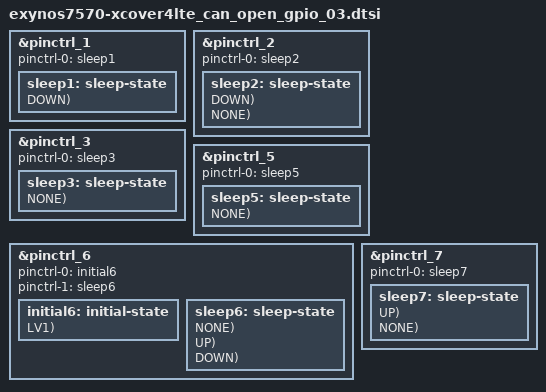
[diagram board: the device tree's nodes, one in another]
/*
 * Copyright (c) 2015 Samsung Electronics Co., Ltd.
 *		http://www.samsung.com
 *
 * This program is free software; you can redistribute it and/or modify
 * it under the terms of the GNU General Public License version 2 as
 * published by the Free Software Foundation.
 */

#include "exynos_gpio_config_macros.dtsi"

/* 0x148C_0000(DISPAUD): gpz1 */
&pinctrl_1 {
	pinctrl-names = "sleep";
	pinctrl-0 = <&sleep1>;
	sleep1: sleep-state {
		PIN_SLP(gpz1-0, INPUT, DOWN);	/* AMP/CODEC_I2S_SYNC :I2S1_LRCK*/
		PIN_SLP(gpz1-1, INPUT, DOWN);	/* AMP_I2S_BCLK */
		PIN_SLP(gpz1-2, INPUT, DOWN);	/* AMP/CODEC_I2S_SDI */
		PIN_SLP(gpz1-3, INPUT, DOWN);	/* AMP/CODEC_I2S_SDO */
		PIN_SLP(gpz1-4, INPUT, DOWN);	/* CODEC_I2S_CLK */
		PIN_SLP(gpz1-5, INPUT, DOWN);	/* SPK_I2C_IN */
		PIN_SLP(gpz1-6, INPUT, DOWN);	/* FM_SPDY_TO_S610 */
	};
};

/* 0x139E_0000(FP): gpc7 */
&pinctrl_2 {
	pinctrl-names = "sleep";
	pinctrl-0 = <&sleep2>;
	sleep2: sleep-state {
		PIN_SLP(gpc7-0, INPUT, DOWN);	/* NC */
		PIN_SLP(gpc7-1, PREV, NONE);	/* PROX_LED_LDO */
		PIN_SLP(gpc7-2, INPUT, DOWN);	/* NC */
		PIN_SLP(gpc7-3, INPUT, DOWN);	/* NC */
		PIN_SLP(gpc7-4, PREV, NONE);	/* FM_LNA_EN */
	};
};

/* 0x1375_0000(FSYS): gpr0~4 */
&pinctrl_3 {
	pinctrl-names = "sleep";
	pinctrl-0 = <&sleep3>;
	sleep3: sleep-state {
		PIN_SLP(gpr0-1, INPUT, NONE);	/* EMMC_CMD */
	};
};

/* 0x1053_0000(MIF): gpm0 */
/* &pinctrl_4 */

/* 0x139C_0000(NFC): gpc2 */
&pinctrl_5 {
	pinctrl-names = "sleep";
	pinctrl-0 = <&sleep5>;
	sleep5: sleep-state {
		PIN_SLP(gpc2-0, INPUT, NONE);	/* LCD_BL_SDA_1P8 */
		PIN_SLP(gpc2-1, INPUT, NONE);	/* LCD_BL_SCL_1P8 */
		PIN_SLP(gpc2-2, PREV, NONE);	/* NFC_PD */
		PIN_SLP(gpc2-3, PREV, NONE);	/* NFC_CLK_REQ */
	};
};

/* 0x139B_0000(TOP): gpc0~1,4, gpd1, gpe0, gpf0~1,3 */
&pinctrl_6 {
	pinctrl-names = "default","sleep";
	pinctrl-0 = <&initial6>;
	pinctrl-1 = <&sleep6>;
	initial6: initial-state {
		PIN_IN(gpd1-2, NONE, LV1);	/* HW_REV0 */
		PIN_IN(gpd1-3, NONE, LV1);	/* HW_REV1 */
		PIN_IN(gpd1-4, NONE, LV1);	/* HW_REV2 */
		PIN_IN(gpd1-5, NONE, LV1);	/* SIM MODE */
		PIN_IN(gpe0-2, DOWN, LV1);	/* NC */

		PIN_OUT_SET(gpf1-1, 0, LV1);	/* MUX_SEL */
	};
	sleep6: sleep-state {
		PIN_SLP(gpc0-1, PREV, NONE);	/* PANEL_EN_P */
		PIN_SLP(gpc0-2, PREV, NONE);	/* PANEL_EN_N */

		PIN_SLP(gpc1-2, PREV, UP);	/* MUIC_I2C_SDA */
		PIN_SLP(gpc1-3, PREV, UP);	/* MUIC_I2C_SCL */

		PIN_SLP(gpc4-0, INPUT, UP);	/* NFC_SDA_1P8 */
		PIN_SLP(gpc4-1, INPUT, UP);	/* NFC_SCL_1P8 */
		PIN_SLP(gpc4-2, INPUT, UP);	/* SENSOR_I2C_SDA */
		PIN_SLP(gpc4-3, INPUT, UP);	/* SENSOR_I2C_SCL */

		PIN_SLP(gpd1-0, PREV, DOWN);	/* NFC_FIRM */
		PIN_SLP(gpd1-1, INPUT, DOWN);	/* CAM_RST_N */
		PIN_SLP(gpd1-2, INPUT, NONE);	/* HW_REV0 */
		PIN_SLP(gpd1-3, INPUT, NONE);	/* HW_REV1 */
		PIN_SLP(gpd1-4, INPUT, NONE);	/* HW_REV2 */
		PIN_SLP(gpd1-5, INPUT, NONE);	/* SIM MODE */
		PIN_SLP(gpd1-6, INPUT, DOWN);	/* VTCAM_RST_N */

		PIN_SLP(gpe0-0, INPUT, DOWN);	/* CAM_MCLK */
		PIN_SLP(gpe0-1, INPUT, DOWN);	/* VTCAM_MCLK */
		PIN_SLP(gpe0-2, INPUT, DOWN);	/* NC */

		PIN_SLP(gpf0-0, INPUT, DOWN);	/* CAM_SDA_1P8 */
		PIN_SLP(gpf0-1, INPUT, DOWN);	/* CAM_SCL_1P8 */
		PIN_SLP(gpf0-2, INPUT, DOWN);	/* CAM_AF_EEP_SDA_1P8 */
		PIN_SLP(gpf0-3, INPUT, DOWN);	/* CAM_AF_EEP_SCL_1P8 */

		PIN_SLP(gpf1-0, OUT1, NONE);	/* NFC_PERI_PWR_EN */
		PIN_SLP(gpf1-1, PREV, NONE);	/* MUX_SEL */

		PIN_SLP(gpf3-0, INPUT, UP);	/* SPK_AMP_SCL */
		PIN_SLP(gpf3-1, INPUT, UP);	/* SPK_AMP_SDA */
		PIN_SLP(gpf3-2, INPUT, DOWN);	/* NC */
		PIN_SLP(gpf3-3, INPUT, DOWN);	/* NC */
	};
};

/* 0x139D_0000(TOUCH): gpc3, gpd2 */
&pinctrl_7 {
	pinctrl-names = "sleep";
	pinctrl-0= <&sleep7>;
	sleep7: sleep-state {
		PIN_SLP(gpc3-0, INPUT, UP);	/* TSP_SDA_1P8 */
		PIN_SLP(gpc3-1, INPUT, UP);	/* TSP_SCL_1P8 */
		PIN_SLP(gpc3-2, INPUT, NONE);	/* TSP_INT */
	};
};
